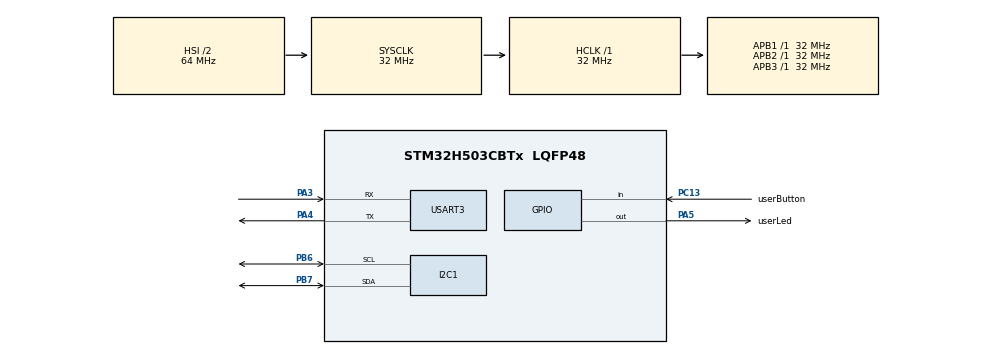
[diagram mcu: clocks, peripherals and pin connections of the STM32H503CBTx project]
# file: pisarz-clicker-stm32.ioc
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BOOTPATH.BootPathName=LEGACY
BOOTPATH.UserSelectedBootPath=LEGACY
CORTEX_M33_NS.Number-Cortex_Memory_Protection_Unit_Region0_OTP_RO_AREAS_Settings=MPU_REGION_NUMBER0
CORTEX_M33_NS.default_mode_Activation=1
I2C1.Timing=0x00707CBB
Mcu.Family=STM32H5
Mcu.Name=STM32H503CBTx
Mcu.Package=LQFP48
NVIC.PriorityGroup=NVIC_PRIORITYGROUP_4
PA3.Mode=Asynchronous
PA3.Signal=USART3_RX
PA4.Mode=Asynchronous
PA4.Signal=USART3_TX
PA5.GPIO_Label=userLed
PA5.Signal=GPIO_Output
PB6.Mode=I2C
PB6.Signal=I2C1_SCL
PB7.Mode=I2C
PB7.Signal=I2C1_SDA
PC13.GPIO_Label=userButton
PC13.Signal=GPIO_Input
ProjectManager.HeapSize=0x200
ProjectManager.StackSize=0x400
ProjectManager.TargetToolchain=Makefile
RCC.ADCFreq_Value=32000000
RCC.AHBFreq_Value=32000000
RCC.APB1Freq_Value=32000000
RCC.APB1TimFreq_Value=32000000
RCC.APB2Freq_Value=32000000
RCC.APB2TimFreq_Value=32000000
RCC.APB3Freq_Value=32000000
RCC.CSI_VALUE=4000000
RCC.CortexFreq_Value=32000000
RCC.EPOD_VALUE=4000000
RCC.HCLKFreq_Value=32000000
RCC.HSE_VALUE=25000000
RCC.HSI48_VALUE=48000000
RCC.HSI_VALUE=64000000
RCC.LSE_VALUE=32768
RCC.LSIRC_VALUE=32000
RCC.SYSCLKFreq_VALUE=32000000
RCC.USBFreq_Value=48000000
RCC.VCOOutputFreq_Value=516000000
USART3.VirtualMode-Asynchronous=VM_ASYNC
VP_BOOTPATH_VS_BOOTPATH.Mode=BP_Activate
VP_CORTEX_M33_NS_VS_Hclk.Mode=Hclk_Mode
VP_ICACHE_VS_ICACHE.Mode=DirectMappedCache
VP_MEMORYMAP_VS_MEMORYMAP.Mode=CurAppReg
VP_PWR_VS_LPOM.Mode=PowerOptimisation
VP_PWR_VS_SECSignals.Mode=Security/Privilege
board=custom

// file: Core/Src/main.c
/* USER CODE BEGIN Header */
/**
  ******************************************************************************
  * @file           : main.c
  * @brief          : Main program body
  ******************************************************************************
  * @attention
  *
  * Copyright (c) 2026 STMicroelectronics.
  * All rights reserved.
  *
  * This software is licensed under terms that can be found in the LICENSE file
  * in the root directory of this software component.
  * If no LICENSE file comes with this software, it is provided AS-IS.
  *
  ******************************************************************************
  */
/* USER CODE END Header */
#include "main.h"
#include "i2c.h"
#include "icache.h"
#include "usart.h"
#include "gpio.h"

/* USER CODE BEGIN Includes */

#include "pca9685.h"

/* USER CODE END Includes */

void SystemClock_Config(void);
static void MPU_Config(void);

int main(void)
{

  /* MCU Configuration--------------------------------------------------------*/

  /* MPU Configuration--------------------------------------------------------*/
  MPU_Config();

  /* Reset of all peripherals, Initializes the Flash interface and the Systick. */
  HAL_Init();

  /* Configure the system clock */
  SystemClock_Config();

  /* Initialize all configured peripherals */
  MX_GPIO_Init();
  MX_ICACHE_Init();
  MX_I2C1_Init();
  MX_USART3_UART_Init();
  /* USER CODE BEGIN 2 */

  pca9685_Init(&hi2c1, 0x40);

  /* USER CODE END 2 */

  /* Infinite loop */
  /* USER CODE BEGIN WHILE */
  while (1)
  {
    for(uint8_t i=0; i<=180; i++){
      pca9685_SetServoAngle(0, i);
      HAL_Delay(10);
    }
    for(int16_t i=180; i>=0; i--){
      pca9685_SetServoAngle(0, i);
      HAL_Delay(10);
    }

    /* USER CODE END WHILE */

  }
}

void SystemClock_Config(void)
{
  RCC_OscInitTypeDef RCC_OscInitStruct = {0};
  RCC_ClkInitTypeDef RCC_ClkInitStruct = {0};

  /** Configure the main internal regulator output voltage
  */
  __HAL_PWR_VOLTAGESCALING_CONFIG(PWR_REGULATOR_VOLTAGE_SCALE3);

  while(!__HAL_PWR_GET_FLAG(PWR_FLAG_VOSRDY)) {}

  /** Initializes the RCC Oscillators according to the specified parameters
  * in the RCC_OscInitTypeDef structure.
  */
  RCC_OscInitStruct.OscillatorType = RCC_OSCILLATORTYPE_HSI;
  RCC_OscInitStruct.HSIState = RCC_HSI_ON;
  RCC_OscInitStruct.HSIDiv = RCC_HSI_DIV2;
  RCC_OscInitStruct.HSICalibrationValue = RCC_HSICALIBRATION_DEFAULT;
  RCC_OscInitStruct.PLL.PLLState = RCC_PLL_NONE;
  if (HAL_RCC_OscConfig(&RCC_OscInitStruct) != HAL_OK)
  {
    Error_Handler();
  }

  /** Initializes the CPU, AHB and APB buses clocks
  */
  RCC_ClkInitStruct.ClockType = RCC_CLOCKTYPE_HCLK|RCC_CLOCKTYPE_SYSCLK
                              |RCC_CLOCKTYPE_PCLK1|RCC_CLOCKTYPE_PCLK2
                              |RCC_CLOCKTYPE_PCLK3;
  RCC_ClkInitStruct.SYSCLKSource = RCC_SYSCLKSOURCE_HSI;
  RCC_ClkInitStruct.AHBCLKDivider = RCC_SYSCLK_DIV1;
  RCC_ClkInitStruct.APB1CLKDivider = RCC_HCLK_DIV1;
  RCC_ClkInitStruct.APB2CLKDivider = RCC_HCLK_DIV1;
  RCC_ClkInitStruct.APB3CLKDivider = RCC_HCLK_DIV1;

  if (HAL_RCC_ClockConfig(&RCC_ClkInitStruct, FLASH_LATENCY_1) != HAL_OK)
  {
    Error_Handler();
  }

  /** Configure the programming delay
  */
  __HAL_FLASH_SET_PROGRAM_DELAY(FLASH_PROGRAMMING_DELAY_0);
}

 /* MPU Configuration */

void MPU_Config(void)
{
  MPU_Region_InitTypeDef MPU_InitStruct = {0};
  MPU_Attributes_InitTypeDef MPU_AttributesInit = {0};

  /* Disables the MPU */
  HAL_MPU_Disable();

  /** Initializes and configures the Region 0 and the memory to be protected
  */
  MPU_InitStruct.Enable = MPU_REGION_ENABLE;
  MPU_InitStruct.Number = MPU_REGION_NUMBER0;
  MPU_InitStruct.BaseAddress = 0x08FFF000;
  MPU_InitStruct.LimitAddress = 0x08FFFFFF;
  MPU_InitStruct.AttributesIndex = MPU_ATTRIBUTES_NUMBER0;
  MPU_InitStruct.AccessPermission = MPU_REGION_ALL_RO;
  MPU_InitStruct.DisableExec = MPU_INSTRUCTION_ACCESS_DISABLE;
  MPU_InitStruct.IsShareable = MPU_ACCESS_NOT_SHAREABLE;

  HAL_MPU_ConfigRegion(&MPU_InitStruct);

  /** Initializes and configures the Attribute 0 and the memory to be protected
  */
  MPU_AttributesInit.Number = MPU_ATTRIBUTES_NUMBER0;
  MPU_AttributesInit.Attributes = INNER_OUTER(MPU_NOT_CACHEABLE);

  HAL_MPU_ConfigMemoryAttributes(&MPU_AttributesInit);
  /* Enables the MPU */
  HAL_MPU_Enable(MPU_PRIVILEGED_DEFAULT);

}

void Error_Handler(void)
{
  __disable_irq();
  while (1)
  {
  }
}
